AUTOSAR XML (schema 4-2-2)
package /AUTOSAR_Dem/SwComponentTypes
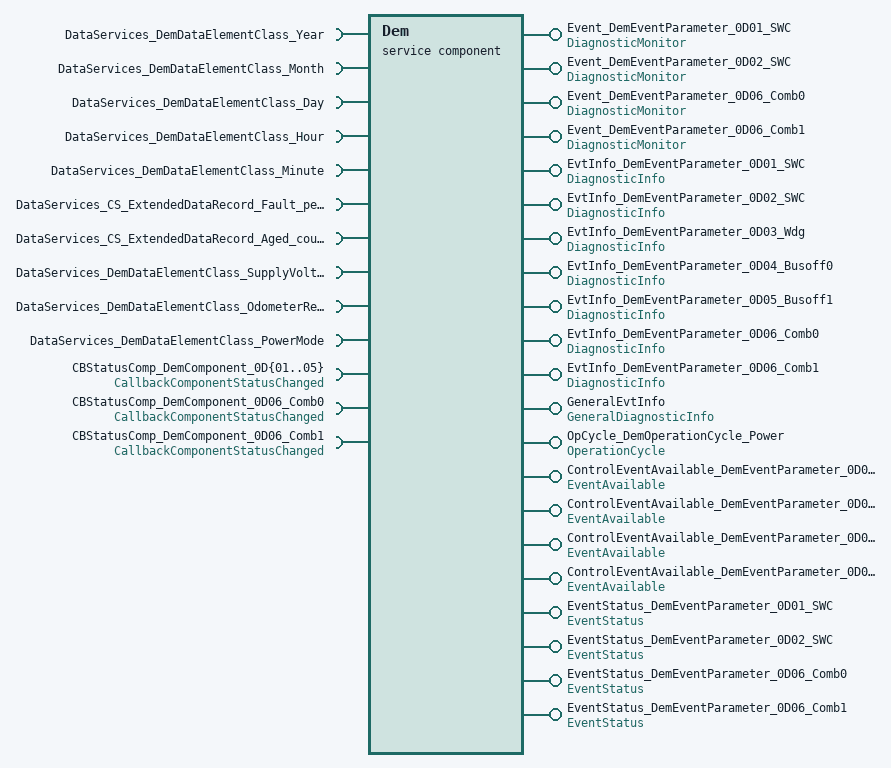
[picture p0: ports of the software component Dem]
  service sw component type Dem
    21 x provide port:
      Event_DemEventParameter_0D01_SWC: provided-interface=DiagnosticMonitor
        provided-com-specs:
          operation=SetEventStatus, queue-length=1
          operation=SetEventStatusWithEnvdata, queue-length=1
          operation=ResetEventStatus, queue-length=1
          operation=PrestoreFreezeFrame, queue-length=1
          operation=ClearPrestoredFreezeFrame, queue-length=1
          operation=ResetEventDebounceStatus, queue-length=1
      Event_DemEventParameter_0D02_SWC: provided-interface=DiagnosticMonitor
        provided-com-specs:
          operation=SetEventStatus, queue-length=1
          operation=SetEventStatusWithEnvdata, queue-length=1
          operation=ResetEventStatus, queue-length=1
          operation=PrestoreFreezeFrame, queue-length=1
          operation=ClearPrestoredFreezeFrame, queue-length=1
          operation=ResetEventDebounceStatus, queue-length=1
      Event_DemEventParameter_0D06_Comb0: provided-interface=DiagnosticMonitor
        provided-com-specs:
          operation=SetEventStatus, queue-length=1
          operation=SetEventStatusWithEnvdata, queue-length=1
          operation=ResetEventStatus, queue-length=1
          operation=PrestoreFreezeFrame, queue-length=1
          operation=ClearPrestoredFreezeFrame, queue-length=1
          operation=ResetEventDebounceStatus, queue-length=1
      Event_DemEventParameter_0D06_Comb1: provided-interface=DiagnosticMonitor
        provided-com-specs:
          operation=SetEventStatus, queue-length=1
          operation=SetEventStatusWithEnvdata, queue-length=1
          operation=ResetEventStatus, queue-length=1
          operation=PrestoreFreezeFrame, queue-length=1
          operation=ClearPrestoredFreezeFrame, queue-length=1
          operation=ResetEventDebounceStatus, queue-length=1
      EvtInfo_DemEventParameter_0D01_SWC: provided-interface=DiagnosticInfo
        provided-com-specs:
          operation=DiagnosticInfo/GetEventStatus, queue-length=1
          operation=DiagnosticInfo/GetEventFailed, queue-length=1
          operation=DiagnosticInfo/GetEventTested, queue-length=1
          operation=DiagnosticInfo/GetDTCOfEvent, queue-length=1
          operation=DiagnosticInfo/GetDebouncingOfEvent, queue-length=1
          operation=DiagnosticInfo/GetFaultDetectionCounter, queue-length=1
          operation=DiagnosticInfo/GetEventExtendedDataRecord, queue-length=1
          operation=DiagnosticInfo/GetEventExtendedDataRecordEx, queue-length=1
          operation=DiagnosticInfo/GetEventFreezeFrameData, queue-length=1
          operation=DiagnosticInfo/GetEventFreezeFrameDataEx, queue-length=1
      EvtInfo_DemEventParameter_0D02_SWC: provided-interface=DiagnosticInfo
        provided-com-specs:
          operation=DiagnosticInfo/GetEventStatus, queue-length=1
          operation=DiagnosticInfo/GetEventFailed, queue-length=1
          operation=DiagnosticInfo/GetEventTested, queue-length=1
          operation=DiagnosticInfo/GetDTCOfEvent, queue-length=1
          operation=DiagnosticInfo/GetDebouncingOfEvent, queue-length=1
          operation=DiagnosticInfo/GetFaultDetectionCounter, queue-length=1
          operation=DiagnosticInfo/GetEventExtendedDataRecord, queue-length=1
          operation=DiagnosticInfo/GetEventExtendedDataRecordEx, queue-length=1
          operation=DiagnosticInfo/GetEventFreezeFrameData, queue-length=1
          operation=DiagnosticInfo/GetEventFreezeFrameDataEx, queue-length=1
      EvtInfo_DemEventParameter_0D03_Wdg: provided-interface=DiagnosticInfo
        provided-com-specs:
          operation=DiagnosticInfo/GetEventStatus, queue-length=1
          operation=DiagnosticInfo/GetEventFailed, queue-length=1
          operation=DiagnosticInfo/GetEventTested, queue-length=1
          operation=DiagnosticInfo/GetDTCOfEvent, queue-length=1
          operation=DiagnosticInfo/GetDebouncingOfEvent, queue-length=1
          operation=DiagnosticInfo/GetFaultDetectionCounter, queue-length=1
          operation=DiagnosticInfo/GetEventExtendedDataRecord, queue-length=1
          operation=DiagnosticInfo/GetEventExtendedDataRecordEx, queue-length=1
          operation=DiagnosticInfo/GetEventFreezeFrameData, queue-length=1
          operation=DiagnosticInfo/GetEventFreezeFrameDataEx, queue-length=1
      EvtInfo_DemEventParameter_0D04_Busoff0: provided-interface=DiagnosticInfo
        provided-com-specs:
          operation=DiagnosticInfo/GetEventStatus, queue-length=1
          operation=DiagnosticInfo/GetEventFailed, queue-length=1
          operation=DiagnosticInfo/GetEventTested, queue-length=1
          operation=DiagnosticInfo/GetDTCOfEvent, queue-length=1
          operation=DiagnosticInfo/GetDebouncingOfEvent, queue-length=1
          operation=DiagnosticInfo/GetFaultDetectionCounter, queue-length=1
          operation=DiagnosticInfo/GetEventExtendedDataRecord, queue-length=1
          operation=DiagnosticInfo/GetEventExtendedDataRecordEx, queue-length=1
          operation=DiagnosticInfo/GetEventFreezeFrameData, queue-length=1
          operation=DiagnosticInfo/GetEventFreezeFrameDataEx, queue-length=1
      EvtInfo_DemEventParameter_0D05_Busoff1: provided-interface=DiagnosticInfo
        provided-com-specs:
          operation=DiagnosticInfo/GetEventStatus, queue-length=1
          operation=DiagnosticInfo/GetEventFailed, queue-length=1
          operation=DiagnosticInfo/GetEventTested, queue-length=1
          operation=DiagnosticInfo/GetDTCOfEvent, queue-length=1
          operation=DiagnosticInfo/GetDebouncingOfEvent, queue-length=1
          operation=DiagnosticInfo/GetFaultDetectionCounter, queue-length=1
          operation=DiagnosticInfo/GetEventExtendedDataRecord, queue-length=1
          operation=DiagnosticInfo/GetEventExtendedDataRecordEx, queue-length=1
          operation=DiagnosticInfo/GetEventFreezeFrameData, queue-length=1
          operation=DiagnosticInfo/GetEventFreezeFrameDataEx, queue-length=1
      EvtInfo_DemEventParameter_0D06_Comb0: provided-interface=DiagnosticInfo
        provided-com-specs:
          operation=DiagnosticInfo/GetEventStatus, queue-length=1
          operation=DiagnosticInfo/GetEventFailed, queue-length=1
          operation=DiagnosticInfo/GetEventTested, queue-length=1
          operation=DiagnosticInfo/GetDTCOfEvent, queue-length=1
          operation=DiagnosticInfo/GetDebouncingOfEvent, queue-length=1
          operation=DiagnosticInfo/GetFaultDetectionCounter, queue-length=1
          operation=DiagnosticInfo/GetEventExtendedDataRecord, queue-length=1
          operation=DiagnosticInfo/GetEventExtendedDataRecordEx, queue-length=1
          operation=DiagnosticInfo/GetEventFreezeFrameData, queue-length=1
          operation=DiagnosticInfo/GetEventFreezeFrameDataEx, queue-length=1
      EvtInfo_DemEventParameter_0D06_Comb1: provided-interface=DiagnosticInfo
        provided-com-specs:
          operation=DiagnosticInfo/GetEventStatus, queue-length=1
          operation=DiagnosticInfo/GetEventFailed, queue-length=1
          operation=DiagnosticInfo/GetEventTested, queue-length=1
          operation=DiagnosticInfo/GetDTCOfEvent, queue-length=1
          operation=DiagnosticInfo/GetDebouncingOfEvent, queue-length=1
          operation=DiagnosticInfo/GetFaultDetectionCounter, queue-length=1
          operation=DiagnosticInfo/GetEventExtendedDataRecord, queue-length=1
          operation=DiagnosticInfo/GetEventExtendedDataRecordEx, queue-length=1
          operation=DiagnosticInfo/GetEventFreezeFrameData, queue-length=1
          operation=DiagnosticInfo/GetEventFreezeFrameDataEx, queue-length=1
      GeneralEvtInfo: provided-interface=GeneralDiagnosticInfo
        provided-com-specs:
          operation=GeneralDiagnosticInfo/GetEventStatus, queue-length=1
          operation=GeneralDiagnosticInfo/GetEventFailed, queue-length=1
          operation=GeneralDiagnosticInfo/GetEventTested, queue-length=1
          operation=GeneralDiagnosticInfo/GetDTCOfEvent, queue-length=1
          operation=GeneralDiagnosticInfo/GetDebouncingOfEvent, queue-length=1
          operation=GeneralDiagnosticInfo/GetFaultDetectionCounter, queue-length=1
          operation=GeneralDiagnosticInfo/GetEventExtendedDataRecord, queue-length=1
          operation=GeneralDiagnosticInfo/GetEventFreezeFrameData, queue-length=1
          operation=GeneralDiagnosticInfo/GetEventExtendedDataRecordEx, queue-length=1
          operation=GeneralDiagnosticInfo/GetEventFreezeFrameDataEx, queue-length=1
          operation=GetEventIdCausingLastDetError, queue-length=1
      OpCycle_DemOperationCycle_Power: provided-interface=OperationCycle
        provided-com-specs:
          operation=SetOperationCycleState, queue-length=1
          operation=GetOperationCycleState, queue-length=1
          operation=GetCycleQualified, queue-length=1
          operation=SetCycleQualified, queue-length=1
      ControlEventAvailable_DemEventParameter_0D01_SWC: server-com-spec{operation=SetEventAvailable, queue-length=1}, provided-interface=EventAvailable
      ControlEventAvailable_DemEventParameter_0D02_SWC: server-com-spec{operation=SetEventAvailable, queue-length=1}, provided-interface=EventAvailable
      ControlEventAvailable_DemEventParameter_0D06_Comb0: server-com-spec{operation=SetEventAvailable, queue-length=1}, provided-interface=EventAvailable
      ControlEventAvailable_DemEventParameter_0D06_Comb1: server-com-spec{operation=SetEventAvailable, queue-length=1}, provided-interface=EventAvailable
      EventStatus_DemEventParameter_0D01_SWC: server-com-spec{operation=SetWIRStatus, queue-length=1}, provided-interface=EventStatus
      EventStatus_DemEventParameter_0D02_SWC: server-com-spec{operation=SetWIRStatus, queue-length=1}, provided-interface=EventStatus
      EventStatus_DemEventParameter_0D06_Comb0: server-com-spec{operation=SetWIRStatus, queue-length=1}, provided-interface=EventStatus
      EventStatus_DemEventParameter_0D06_Comb1: server-com-spec{operation=SetWIRStatus, queue-length=1}, provided-interface=EventStatus
    17 x require port:
      DataServices_DemDataElementClass_Year: required-interface=DataServices_DemDataElementClass_Year
      DataServices_DemDataElementClass_Month: required-interface=DataServices_DemDataElementClass_Month
      DataServices_DemDataElementClass_Day: required-interface=DataServices_DemDataElementClass_Day
      DataServices_DemDataElementClass_Hour: required-interface=DataServices_DemDataElementClass_Hour
      DataServices_DemDataElementClass_Minute: required-interface=DataServices_DemDataElementClass_Minute
      DataServices_CS_ExtendedDataRecord_Fault_pending_counter: required-interface=DataServices_CS_ExtendedDataRecord_Fault_pending_counter
      DataServices_CS_ExtendedDataRecord_Aged_counter: required-interface=DataServices_CS_ExtendedDataRecord_Aged_counter
      DataServices_DemDataElementClass_SupplyVoltage: required-interface=DataServices_DemDataElementClass_SupplyVoltage
      DataServices_DemDataElementClass_OdometerReading: required-interface=DataServices_DemDataElementClass_OdometerReading
      DataServices_DemDataElementClass_PowerMode: required-interface=DataServices_DemDataElementClass_PowerMode
      CBStatusComp_DemComponent_0D{01..05}: required-interface=CallbackComponentStatusChanged
      CBStatusComp_DemComponent_0D06_Comb0: required-interface=CallbackComponentStatusChanged
      CBStatusComp_DemComponent_0D06_Comb1: required-interface=CallbackComponentStatusChanged
    behavior IntBeh_Dem: handle-termination-and-restart=NO-SUPPORT, included-data-type-set=data-type=[Dem_DTCFormatType, Dem_DTCOriginType, Dem_EventIdType, Dem_UdsStatusByteType, Dem_EventStatusType, Dem_DebugDataType, Dem_IndicatorIdType, Dem_IndicatorStatusType, Dem_InitMonitorReasonType, Dem_MaxDataValueType, Dem_OperationCycleIdType, Dem_OperationCycleStateType, Dem_DebouncingStateType, Dem_DebounceResetStatusType]
      117 x operation invoked event:
        Ev_SES_DemEventParameter_0D01_SWC: start-on-event=SetEventStatus, operation=Event_DemEventParameter_0D01_SWC.SetEventStatus
        Ev_SESWE_DemEventParameter_0D01_SWC: start-on-event=SetEventStatusWithEnvdata, operation=Event_DemEventParameter_0D01_SWC.SetEventStatusWithEnvdata
        Ev_RES_DemEventParameter_0D01_SWC: start-on-event=ResetEventStatus, operation=Event_DemEventParameter_0D01_SWC.ResetEventStatus
        Ev_CPFF_DemEventParameter_0D01_SWC: start-on-event=ClearPrestoredFreezeFrame, operation=Event_DemEventParameter_0D01_SWC.ClearPrestoredFreezeFrame
        Ev_PFF_DemEventParameter_0D01_SWC: start-on-event=PrestoreFreezeFrame, operation=Event_DemEventParameter_0D01_SWC.PrestoreFreezeFrame
        Ev_RDS_DemEventParameter_0D01_SWC: start-on-event=ResetEventDebounceStatus, operation=Event_DemEventParameter_0D01_SWC.ResetEventDebounceStatus
        Ev_SES_DemEventParameter_0D02_SWC: start-on-event=SetEventStatus, operation=Event_DemEventParameter_0D02_SWC.SetEventStatus
        Ev_SESWE_DemEventParameter_0D02_SWC: start-on-event=SetEventStatusWithEnvdata, operation=Event_DemEventParameter_0D02_SWC.SetEventStatusWithEnvdata
        Ev_RES_DemEventParameter_0D02_SWC: start-on-event=ResetEventStatus, operation=Event_DemEventParameter_0D02_SWC.ResetEventStatus
        Ev_CPFF_DemEventParameter_0D02_SWC: start-on-event=ClearPrestoredFreezeFrame, operation=Event_DemEventParameter_0D02_SWC.ClearPrestoredFreezeFrame
        Ev_PFF_DemEventParameter_0D02_SWC: start-on-event=PrestoreFreezeFrame, operation=Event_DemEventParameter_0D02_SWC.PrestoreFreezeFrame
        Ev_RDS_DemEventParameter_0D02_SWC: start-on-event=ResetEventDebounceStatus, operation=Event_DemEventParameter_0D02_SWC.ResetEventDebounceStatus
        Ev_SES_DemEventParameter_0D06_Comb0: start-on-event=SetEventStatus, operation=Event_DemEventParameter_0D06_Comb0.SetEventStatus
        Ev_SESWE_DemEventParameter_0D06_Comb0: start-on-event=SetEventStatusWithEnvdata, operation=Event_DemEventParameter_0D06_Comb0.SetEventStatusWithEnvdata
        Ev_RES_DemEventParameter_0D06_Comb0: start-on-event=ResetEventStatus, operation=Event_DemEventParameter_0D06_Comb0.ResetEventStatus
        Ev_CPFF_DemEventParameter_0D06_Comb0: start-on-event=ClearPrestoredFreezeFrame, operation=Event_DemEventParameter_0D06_Comb0.ClearPrestoredFreezeFrame
        Ev_PFF_DemEventParameter_0D06_Comb0: start-on-event=PrestoreFreezeFrame, operation=Event_DemEventParameter_0D06_Comb0.PrestoreFreezeFrame
        Ev_RDS_DemEventParameter_0D06_Comb0: start-on-event=ResetEventDebounceStatus, operation=Event_DemEventParameter_0D06_Comb0.ResetEventDebounceStatus
        Ev_SES_DemEventParameter_0D06_Comb1: start-on-event=SetEventStatus, operation=Event_DemEventParameter_0D06_Comb1.SetEventStatus
        Ev_SESWE_DemEventParameter_0D06_Comb1: start-on-event=SetEventStatusWithEnvdata, operation=Event_DemEventParameter_0D06_Comb1.SetEventStatusWithEnvdata
        Ev_RES_DemEventParameter_0D06_Comb1: start-on-event=ResetEventStatus, operation=Event_DemEventParameter_0D06_Comb1.ResetEventStatus
        Ev_CPFF_DemEventParameter_0D06_Comb1: start-on-event=ClearPrestoredFreezeFrame, operation=Event_DemEventParameter_0D06_Comb1.ClearPrestoredFreezeFrame
        Ev_PFF_DemEventParameter_0D06_Comb1: start-on-event=PrestoreFreezeFrame, operation=Event_DemEventParameter_0D06_Comb1.PrestoreFreezeFrame
        Ev_RDS_DemEventParameter_0D06_Comb1: start-on-event=ResetEventDebounceStatus, operation=Event_DemEventParameter_0D06_Comb1.ResetEventDebounceStatus
        Ev_GES_DemEventParameter_0D01_SWC: start-on-event=GetEventStatus, operation=EvtInfo_DemEventParameter_0D01_SWC.GetEventStatus
        Ev_GEF_DemEventParameter_0D01_SWC: start-on-event=GetEventFailed, operation=EvtInfo_DemEventParameter_0D01_SWC.GetEventFailed
        Ev_GET_DemEventParameter_0D01_SWC: start-on-event=GetEventTested, operation=EvtInfo_DemEventParameter_0D01_SWC.GetEventTested
        Ev_GDOE_DemEventParameter_0D01_SWC: start-on-event=GetDTCOfEvent, operation=EvtInfo_DemEventParameter_0D01_SWC.GetDTCOfEvent
        Ev_GETDOE_DemEventParameter_0D01_SWC: start-on-event=GetDebouncingOfEvent, operation=EvtInfo_DemEventParameter_0D01_SWC.GetDebouncingOfEvent
        Ev_GFDC_DemEventParameter_0D01_SWC: start-on-event=GetFaultDetectionCounter, operation=EvtInfo_DemEventParameter_0D01_SWC.GetFaultDetectionCounter
        Ev_GEED_DemEventParameter_0D01_SWC: start-on-event=GetEventExtendedDataRecord, operation=EvtInfo_DemEventParameter_0D01_SWC.GetEventExtendedDataRecord
        Ev_GEEDR_DemEventParameter_0D01_SWC: start-on-event=GetEventExtendedDataRecordEx, operation=EvtInfo_DemEventParameter_0D01_SWC.GetEventExtendedDataRecordEx
        Ev_GEFFD_DemEventParameter_0D01_SWC: start-on-event=GetEventFreezeFrameData, operation=EvtInfo_DemEventParameter_0D01_SWC.GetEventFreezeFrameData
        Ev_GEFFDE_DemEventParameter_0D01_SWC: start-on-event=GetEventFreezeFrameDataEx, operation=EvtInfo_DemEventParameter_0D01_SWC.GetEventFreezeFrameDataEx
        Ev_GES_DemEventParameter_0D02_SWC: start-on-event=GetEventStatus, operation=EvtInfo_DemEventParameter_0D02_SWC.GetEventStatus
        Ev_GEF_DemEventParameter_0D02_SWC: start-on-event=GetEventFailed, operation=EvtInfo_DemEventParameter_0D02_SWC.GetEventFailed
        Ev_GET_DemEventParameter_0D02_SWC: start-on-event=GetEventTested, operation=EvtInfo_DemEventParameter_0D02_SWC.GetEventTested
        Ev_GDOE_DemEventParameter_0D02_SWC: start-on-event=GetDTCOfEvent, operation=EvtInfo_DemEventParameter_0D02_SWC.GetDTCOfEvent
        Ev_GETDOE_DemEventParameter_0D02_SWC: start-on-event=GetDebouncingOfEvent, operation=EvtInfo_DemEventParameter_0D02_SWC.GetDebouncingOfEvent
        Ev_GFDC_DemEventParameter_0D02_SWC: start-on-event=GetFaultDetectionCounter, operation=EvtInfo_DemEventParameter_0D02_SWC.GetFaultDetectionCounter
        Ev_GEED_DemEventParameter_0D02_SWC: start-on-event=GetEventExtendedDataRecord, operation=EvtInfo_DemEventParameter_0D02_SWC.GetEventExtendedDataRecord
        Ev_GEEDR_DemEventParameter_0D02_SWC: start-on-event=GetEventExtendedDataRecordEx, operation=EvtInfo_DemEventParameter_0D02_SWC.GetEventExtendedDataRecordEx
        Ev_GEFFD_DemEventParameter_0D02_SWC: start-on-event=GetEventFreezeFrameData, operation=EvtInfo_DemEventParameter_0D02_SWC.GetEventFreezeFrameData
        Ev_GEFFDE_DemEventParameter_0D02_SWC: start-on-event=GetEventFreezeFrameDataEx, operation=EvtInfo_DemEventParameter_0D02_SWC.GetEventFreezeFrameDataEx
        Ev_GES_DemEventParameter_0D03_Wdg: start-on-event=GetEventStatus, operation=EvtInfo_DemEventParameter_0D03_Wdg.GetEventStatus
        Ev_GEF_DemEventParameter_0D03_Wdg: start-on-event=GetEventFailed, operation=EvtInfo_DemEventParameter_0D03_Wdg.GetEventFailed
        Ev_GET_DemEventParameter_0D03_Wdg: start-on-event=GetEventTested, operation=EvtInfo_DemEventParameter_0D03_Wdg.GetEventTested
        Ev_GDOE_DemEventParameter_0D03_Wdg: start-on-event=GetDTCOfEvent, operation=EvtInfo_DemEventParameter_0D03_Wdg.GetDTCOfEvent
        Ev_GETDOE_DemEventParameter_0D03_Wdg: start-on-event=GetDebouncingOfEvent, operation=EvtInfo_DemEventParameter_0D03_Wdg.GetDebouncingOfEvent
        Ev_GFDC_DemEventParameter_0D03_Wdg: start-on-event=GetFaultDetectionCounter, operation=EvtInfo_DemEventParameter_0D03_Wdg.GetFaultDetectionCounter
        Ev_GEED_DemEventParameter_0D03_Wdg: start-on-event=GetEventExtendedDataRecord, operation=EvtInfo_DemEventParameter_0D03_Wdg.GetEventExtendedDataRecord
        Ev_GEEDR_DemEventParameter_0D03_Wdg: start-on-event=GetEventExtendedDataRecordEx, operation=EvtInfo_DemEventParameter_0D03_Wdg.GetEventExtendedDataRecordEx
        Ev_GEFFD_DemEventParameter_0D03_Wdg: start-on-event=GetEventFreezeFrameData, operation=EvtInfo_DemEventParameter_0D03_Wdg.GetEventFreezeFrameData
        Ev_GEFFDE_DemEventParameter_0D03_Wdg: start-on-event=GetEventFreezeFrameDataEx, operation=EvtInfo_DemEventParameter_0D03_Wdg.GetEventFreezeFrameDataEx
        Ev_GES_DemEventParameter_0D04_Busoff0: start-on-event=GetEventStatus, operation=EvtInfo_DemEventParameter_0D04_Busoff0.GetEventStatus
        Ev_GEF_DemEventParameter_0D04_Busoff0: start-on-event=GetEventFailed, operation=EvtInfo_DemEventParameter_0D04_Busoff0.GetEventFailed
        Ev_GET_DemEventParameter_0D04_Busoff0: start-on-event=GetEventTested, operation=EvtInfo_DemEventParameter_0D04_Busoff0.GetEventTested
        Ev_GDOE_DemEventParameter_0D04_Busoff0: start-on-event=GetDTCOfEvent, operation=EvtInfo_DemEventParameter_0D04_Busoff0.GetDTCOfEvent
        Ev_GETDOE_DemEventParameter_0D04_Busoff0: start-on-event=GetDebouncingOfEvent, operation=EvtInfo_DemEventParameter_0D04_Busoff0.GetDebouncingOfEvent
        Ev_GFDC_DemEventParameter_0D04_Busoff0: start-on-event=GetFaultDetectionCounter, operation=EvtInfo_DemEventParameter_0D04_Busoff0.GetFaultDetectionCounter
        Ev_GEED_DemEventParameter_0D04_Busoff0: start-on-event=GetEventExtendedDataRecord, operation=EvtInfo_DemEventParameter_0D04_Busoff0.GetEventExtendedDataRecord
        Ev_GEEDR_DemEventParameter_0D04_Busoff0: start-on-event=GetEventExtendedDataRecordEx, operation=EvtInfo_DemEventParameter_0D04_Busoff0.GetEventExtendedDataRecordEx
        Ev_GEFFD_DemEventParameter_0D04_Busoff0: start-on-event=GetEventFreezeFrameData, operation=EvtInfo_DemEventParameter_0D04_Busoff0.GetEventFreezeFrameData
        Ev_GEFFDE_DemEventParameter_0D04_Busoff0: start-on-event=GetEventFreezeFrameDataEx, operation=EvtInfo_DemEventParameter_0D04_Busoff0.GetEventFreezeFrameDataEx
        Ev_GES_DemEventParameter_0D05_Busoff1: start-on-event=GetEventStatus, operation=EvtInfo_DemEventParameter_0D05_Busoff1.GetEventStatus
        Ev_GEF_DemEventParameter_0D05_Busoff1: start-on-event=GetEventFailed, operation=EvtInfo_DemEventParameter_0D05_Busoff1.GetEventFailed
        Ev_GET_DemEventParameter_0D05_Busoff1: start-on-event=GetEventTested, operation=EvtInfo_DemEventParameter_0D05_Busoff1.GetEventTested
        Ev_GDOE_DemEventParameter_0D05_Busoff1: start-on-event=GetDTCOfEvent, operation=EvtInfo_DemEventParameter_0D05_Busoff1.GetDTCOfEvent
        Ev_GETDOE_DemEventParameter_0D05_Busoff1: start-on-event=GetDebouncingOfEvent, operation=EvtInfo_DemEventParameter_0D05_Busoff1.GetDebouncingOfEvent
        Ev_GFDC_DemEventParameter_0D05_Busoff1: start-on-event=GetFaultDetectionCounter, operation=EvtInfo_DemEventParameter_0D05_Busoff1.GetFaultDetectionCounter
        Ev_GEED_DemEventParameter_0D05_Busoff1: start-on-event=GetEventExtendedDataRecord, operation=EvtInfo_DemEventParameter_0D05_Busoff1.GetEventExtendedDataRecord
        Ev_GEEDR_DemEventParameter_0D05_Busoff1: start-on-event=GetEventExtendedDataRecordEx, operation=EvtInfo_DemEventParameter_0D05_Busoff1.GetEventExtendedDataRecordEx
        Ev_GEFFD_DemEventParameter_0D05_Busoff1: start-on-event=GetEventFreezeFrameData, operation=EvtInfo_DemEventParameter_0D05_Busoff1.GetEventFreezeFrameData
        Ev_GEFFDE_DemEventParameter_0D05_Busoff1: start-on-event=GetEventFreezeFrameDataEx, operation=EvtInfo_DemEventParameter_0D05_Busoff1.GetEventFreezeFrameDataEx
        Ev_GES_DemEventParameter_0D06_Comb0: start-on-event=GetEventStatus, operation=EvtInfo_DemEventParameter_0D06_Comb0.GetEventStatus
        Ev_GEF_DemEventParameter_0D06_Comb0: start-on-event=GetEventFailed, operation=EvtInfo_DemEventParameter_0D06_Comb0.GetEventFailed
        Ev_GET_DemEventParameter_0D06_Comb0: start-on-event=GetEventTested, operation=EvtInfo_DemEventParameter_0D06_Comb0.GetEventTested
        Ev_GDOE_DemEventParameter_0D06_Comb0: start-on-event=GetDTCOfEvent, operation=EvtInfo_DemEventParameter_0D06_Comb0.GetDTCOfEvent
        Ev_GETDOE_DemEventParameter_0D06_Comb0: start-on-event=GetDebouncingOfEvent, operation=EvtInfo_DemEventParameter_0D06_Comb0.GetDebouncingOfEvent
        Ev_GFDC_DemEventParameter_0D06_Comb0: start-on-event=GetFaultDetectionCounter, operation=EvtInfo_DemEventParameter_0D06_Comb0.GetFaultDetectionCounter
        Ev_GEED_DemEventParameter_0D06_Comb0: start-on-event=GetEventExtendedDataRecord, operation=EvtInfo_DemEventParameter_0D06_Comb0.GetEventExtendedDataRecord
        Ev_GEEDR_DemEventParameter_0D06_Comb0: start-on-event=GetEventExtendedDataRecordEx, operation=EvtInfo_DemEventParameter_0D06_Comb0.GetEventExtendedDataRecordEx
        Ev_GEFFD_DemEventParameter_0D06_Comb0: start-on-event=GetEventFreezeFrameData, operation=EvtInfo_DemEventParameter_0D06_Comb0.GetEventFreezeFrameData
        Ev_GEFFDE_DemEventParameter_0D06_Comb0: start-on-event=GetEventFreezeFrameDataEx, operation=EvtInfo_DemEventParameter_0D06_Comb0.GetEventFreezeFrameDataEx
        Ev_GES_DemEventParameter_0D06_Comb1: start-on-event=GetEventStatus, operation=EvtInfo_DemEventParameter_0D06_Comb1.GetEventStatus
        Ev_GEF_DemEventParameter_0D06_Comb1: start-on-event=GetEventFailed, operation=EvtInfo_DemEventParameter_0D06_Comb1.GetEventFailed
        Ev_GET_DemEventParameter_0D06_Comb1: start-on-event=GetEventTested, operation=EvtInfo_DemEventParameter_0D06_Comb1.GetEventTested
        Ev_GDOE_DemEventParameter_0D06_Comb1: start-on-event=GetDTCOfEvent, operation=EvtInfo_DemEventParameter_0D06_Comb1.GetDTCOfEvent
        Ev_GETDOE_DemEventParameter_0D06_Comb1: start-on-event=GetDebouncingOfEvent, operation=EvtInfo_DemEventParameter_0D06_Comb1.GetDebouncingOfEvent
        Ev_GFDC_DemEventParameter_0D06_Comb1: start-on-event=GetFaultDetectionCounter, operation=EvtInfo_DemEventParameter_0D06_Comb1.GetFaultDetectionCounter
        Ev_GEED_DemEventParameter_0D06_Comb1: start-on-event=GetEventExtendedDataRecord, operation=EvtInfo_DemEventParameter_0D06_Comb1.GetEventExtendedDataRecord
        Ev_GEEDR_DemEventParameter_0D06_Comb1: start-on-event=GetEventExtendedDataRecordEx, operation=EvtInfo_DemEventParameter_0D06_Comb1.GetEventExtendedDataRecordEx
        Ev_GEFFD_DemEventParameter_0D06_Comb1: start-on-event=GetEventFreezeFrameData, operation=EvtInfo_DemEventParameter_0D06_Comb1.GetEventFreezeFrameData
        Ev_GEFFDE_DemEventParameter_0D06_Comb1: start-on-event=GetEventFreezeFrameDataEx, operation=EvtInfo_DemEventParameter_0D06_Comb1.GetEventFreezeFrameDataEx
        GDI_GDOE_GetDebouncingOfEvent: start-on-event=GetDebouncingOfEvent_GeneralEvtInfo, operation=GeneralEvtInfo.GetDebouncingOfEvent
        GDI_GES_GetEventStatus: start-on-event=Dem_GetEventStatus_GeneralEvtInfo, operation=GeneralEvtInfo.GetEventStatus
        GDI_GEF_GetEventFailed: start-on-event=Dem_GetEventFailed_GeneralEvtInfo, operation=GeneralEvtInfo.GetEventFailed
        GDI_GET_GetEventTested: start-on-event=Dem_GetEventTested_GeneralEvtInfo, operation=GeneralEvtInfo.GetEventTested
        GDI_GDE_GetDTCOfEvent: start-on-event=Dem_GetDTCOfEvent_GeneralEvtInfo, operation=GeneralEvtInfo.GetDTCOfEvent
        GDI_GFDC_GetFaultDetectionCounter: start-on-event=Dem_GetFaultDetectionCounter_GeneralEvtInfo, operation=GeneralEvtInfo.GetFaultDetectionCounter
        GDI_GEED_GetEventExtendedDataRecord: start-on-event=Dem_GetEventExtendedDataRecord_GeneralEvtInfo, operation=GeneralEvtInfo.GetEventExtendedDataRecord
        GDI_GEFFD_GetEventFreezeFrameData: start-on-event=Dem_GetEventFreezeFrameData_GeneralEvtInfo, operation=GeneralEvtInfo.GetEventFreezeFrameData
        GDI_GEED_GetEventExtendedDataRecordEx: start-on-event=Dem_GetEventExtendedDataRecordEx_GeneralEvtInfo, operation=GeneralEvtInfo.GetEventExtendedDataRecordEx
        GDI_GEFFD_GetEventFreezeFrameDataEx: start-on-event=Dem_GetEventFreezeFrameDataEx_GeneralEvtInfo, operation=GeneralEvtInfo.GetEventFreezeFrameDataEx
        Ev_GEICLDE_GetEventIdCausingLastDetError: start-on-event=Dem_GetEventIdCausingLastDetError, operation=GeneralEvtInfo.GetEventIdCausingLastDetError
        OpCycle_OCS_DemOperationCycle_Power: start-on-event=SetOperationCycleState, operation=OpCycle_DemOperationCycle_Power.SetOperationCycleState
        OpCycle_GOCS_DemOperationCycle_Power: start-on-event=GetOperationCycleState, operation=OpCycle_DemOperationCycle_Power.GetOperationCycleState
        OpCycle_GCQ_DemOperationCycle_Power: start-on-event=GetCycleQualified, operation=OpCycle_DemOperationCycle_Power.GetCycleQualified
        OpCycle_SCQ_DemOperationCycle_Power: start-on-event=SetCycleQualified, operation=OpCycle_DemOperationCycle_Power.SetCycleQualified
        Ev_SetWIRStatus_DemEventParameter_0D01_SWC: start-on-event=SetWIRStatus, operation=EventStatus_DemEventParameter_0D01_SWC.SetWIRStatus
        Ev_SetWIRStatus_DemEventParameter_0D02_SWC: start-on-event=SetWIRStatus, operation=EventStatus_DemEventParameter_0D02_SWC.SetWIRStatus
        Ev_SetWIRStatus_DemEventParameter_0D06_Comb0: start-on-event=SetWIRStatus, operation=EventStatus_DemEventParameter_0D06_Comb0.SetWIRStatus
        Ev_SetWIRStatus_DemEventParameter_0D06_Comb1: start-on-event=SetWIRStatus, operation=EventStatus_DemEventParameter_0D06_Comb1.SetWIRStatus
        EventAvailable_SetEventAvailable_DemEventParameter_0D01_SWC: start-on-event=SetEventAvailable, operation=ControlEventAvailable_DemEventParameter_0D01_SWC.SetEventAvailable
        EventAvailable_SetEventAvailable_DemEventParameter_0D02_SWC: start-on-event=SetEventAvailable, operation=ControlEventAvailable_DemEventParameter_0D02_SWC.SetEventAvailable
        EventAvailable_SetEventAvailable_DemEventParameter_0D06_Comb0: start-on-event=SetEventAvailable, operation=ControlEventAvailable_DemEventParameter_0D06_Comb0.SetEventAvailable
        EventAvailable_SetEventAvailable_DemEventParameter_0D06_Comb1: start-on-event=SetEventAvailable, operation=ControlEventAvailable_DemEventParameter_0D06_Comb1.SetEventAvailable
      port-api-options:
        {enable-take-address=true, indirect-api=false, port-defined-argument-value{value=EvtInfo_DemEventParameter_0D01_SWC:1, value-type=Dem_EventIdType}, port=EvtInfo_DemEventParameter_0D01_SWC}
        {enable-take-address=true, indirect-api=false, port-defined-argument-value{value=EvtInfo_DemEventParameter_0D02_SWC:2, value-type=Dem_EventIdType}, port=EvtInfo_DemEventParameter_0D02_SWC}
        {enable-take-address=true, indirect-api=false, port-defined-argument-value{value=EvtInfo_DemEventParameter_0D03_Wdg:3, value-type=Dem_EventIdType}, port=EvtInfo_DemEventParameter_0D03_Wdg}
        {enable-take-address=true, indirect-api=false, port-defined-argument-value{value=EvtInfo_DemEventParameter_0D04_Busoff0:4, value-type=Dem_EventIdType}, port=EvtInfo_DemEventParameter_0D04_Busoff0}
        {enable-take-address=true, indirect-api=false, port-defined-argument-value{value=EvtInfo_DemEventParameter_0D05_Busoff1:5, value-type=Dem_EventIdType}, port=EvtInfo_DemEventParameter_0D05_Busoff1}
        {enable-take-address=true, indirect-api=false, port-defined-argument-value{value=EvtInfo_DemEventParameter_0D06_Comb0:6, value-type=Dem_EventIdType}, port=EvtInfo_DemEventParameter_0D06_Comb0}
        {enable-take-address=true, indirect-api=false, port-defined-argument-value{value=EvtInfo_DemEventParameter_0D06_Comb1:7, value-type=Dem_EventIdType}, port=EvtInfo_DemEventParameter_0D06_Comb1}
        {enable-take-address=true, indirect-api=false, port-defined-argument-value{value=Event_DemEventParameter_0D01_SWC:1, value-type=Dem_EventIdType}, port=Event_DemEventParameter_0D01_SWC}
        {enable-take-address=true, indirect-api=false, port-defined-argument-value{value=EventStatus_DemEventParameter_0D01_SWC:1, value-type=Dem_EventIdType}, port=EventStatus_DemEventParameter_0D01_SWC}
        {enable-take-address=true, indirect-api=false, port-defined-argument-value{value=Event_DemEventParameter_0D02_SWC:2, value-type=Dem_EventIdType}, port=Event_DemEventParameter_0D02_SWC}
        {enable-take-address=true, indirect-api=false, port-defined-argument-value{value=EventStatus_DemEventParameter_0D02_SWC:2, value-type=Dem_EventIdType}, port=EventStatus_DemEventParameter_0D02_SWC}
        {enable-take-address=true, indirect-api=false, port-defined-argument-value{value=Event_DemEventParameter_0D06_Comb0:6, value-type=Dem_EventIdType}, port=Event_DemEventParameter_0D06_Comb0}
        {enable-take-address=true, indirect-api=false, port-defined-argument-value{value=EventStatus_DemEventParameter_0D06_Comb0:6, value-type=Dem_EventIdType}, port=EventStatus_DemEventParameter_0D06_Comb0}
        {enable-take-address=true, indirect-api=false, port-defined-argument-value{value=Event_DemEventParameter_0D06_Comb1:7, value-type=Dem_EventIdType}, port=Event_DemEventParameter_0D06_Comb1}
        {enable-take-address=true, indirect-api=false, port-defined-argument-value{value=EventStatus_DemEventParameter_0D06_Comb1:7, value-type=Dem_EventIdType}, port=EventStatus_DemEventParameter_0D06_Comb1}
        {enable-take-address=true, indirect-api=false, port-defined-argument-value{value=OpCycle_DemOperationCycle_Power:0, value-type=Dem_OperationCycleIdType}, port=OpCycle_DemOperationCycle_Power}
        enable-take-address=true, indirect-api=false, port=GeneralEvtInfo
        {enable-take-address=true, indirect-api=false, port-defined-argument-value{value=ControlEventAvailable_DemEventParameter_0D01_SWC:1, value-type=Dem_EventIdType}, port=ControlEventAvailable_DemEventParameter_0D01_SWC}
        {enable-take-address=true, indirect-api=false, port-defined-argument-value{value=ControlEventAvailable_DemEventParameter_0D02_SWC:2, value-type=Dem_EventIdType}, port=ControlEventAvailable_DemEventParameter_0D02_SWC}
        {enable-take-address=true, indirect-api=false, port-defined-argument-value{value=ControlEventAvailable_DemEventParameter_0D06_Comb0:6, value-type=Dem_EventIdType}, port=ControlEventAvailable_DemEventParameter_0D06_Comb0}
        {enable-take-address=true, indirect-api=false, port-defined-argument-value{value=ControlEventAvailable_DemEventParameter_0D06_Comb1:7, value-type=Dem_EventIdType}, port=ControlEventAvailable_DemEventParameter_0D06_Comb1}
        enable-take-address=true, indirect-api=false, port=DataServices_DemDataElementClass_Year
        enable-take-address=true, indirect-api=false, port=DataServices_DemDataElementClass_Month
        enable-take-address=true, indirect-api=false, port=DataServices_DemDataElementClass_Day
        enable-take-address=true, indirect-api=false, port=DataServices_DemDataElementClass_Hour
        enable-take-address=true, indirect-api=false, port=DataServices_DemDataElementClass_Minute
        enable-take-address=true, indirect-api=false, port=DataServices_CS_ExtendedDataRecord_Fault_pending_counter
        enable-take-address=true, indirect-api=false, port=DataServices_CS_ExtendedDataRecord_Aged_counter
        enable-take-address=true, indirect-api=false, port=DataServices_DemDataElementClass_SupplyVoltage
        enable-take-address=true, indirect-api=false, port=DataServices_DemDataElementClass_OdometerReading
        enable-take-address=true, indirect-api=false, port=DataServices_DemDataElementClass_PowerMode
      45 x runnable:
        Dem_MainFunction
          17 x sync call, all with timeout=0.0:
            SSC_DataServices_DemDataElementClass_Year_ReadData: operation=DataServices_DemDataElementClass_Year.ReadData
            SSC_DataServices_DemDataElementClass_Month_ReadData: operation=DataServices_DemDataElementClass_Month.ReadData
            SSC_DataServices_DemDataElementClass_Day_ReadData: operation=DataServices_DemDataElementClass_Day.ReadData
            SSC_DataServices_DemDataElementClass_Hour_ReadData: operation=DataServices_DemDataElementClass_Hour.ReadData
            SSC_DataServices_DemDataElementClass_Minute_ReadData: operation=DataServices_DemDataElementClass_Minute.ReadData
            SSC_DataServices_CS_ExtendedDataRecord_Fault_pending_counter_ReadData: operation=DataServices_CS_ExtendedDataRecord_Fault_pending_counter.ReadData
            SSC_DataServices_CS_ExtendedDataRecord_Aged_counter_ReadData: operation=DataServices_CS_ExtendedDataRecord_Aged_counter.ReadData
            SSC_DataServices_DemDataElementClass_SupplyVoltage_ReadData: operation=DataServices_DemDataElementClass_SupplyVoltage.ReadData
            SSC_DataServices_DemDataElementClass_OdometerReading_ReadData: operation=DataServices_DemDataElementClass_OdometerReading.ReadData
            SSC_DataServices_DemDataElementClass_PowerMode_ReadData: operation=DataServices_DemDataElementClass_PowerMode.ReadData
            SSC_CBStatusComp_DemComponent_0D{01..05}: operation=CBStatusComp_DemComponent_0D{01..05}.ComponentStatusChanged
            SSC_CBStatusComp_DemComponent_0D06_Comb0: operation=CBStatusComp_DemComponent_0D06_Comb0.ComponentStatusChanged
            SSC_CBStatusComp_DemComponent_0D06_Comb1: operation=CBStatusComp_DemComponent_0D06_Comb1.ComponentStatusChanged
        SetEventStatus: arguments=[symbol=EventId, symbol=EventStatus], can-be-invoked-concurrently=true, symbol=Dem_SetEventStatus
        SetEventStatusWithEnvdata: arguments=[symbol=EventId, symbol=EventStatus, symbol=debug0, symbol=debug1], can-be-invoked-concurrently=true, symbol=Dem_SetEventStatusWithEnvData
        ResetEventStatus: runnable-entity-argument=symbol=EventId, can-be-invoked-concurrently=true, symbol=Dem_ResetEventStatus
        PrestoreFreezeFrame: runnable-entity-argument=symbol=EventId, can-be-invoked-concurrently=true, symbol=Dem_PrestoreFreezeFrame
        ClearPrestoredFreezeFrame: runnable-entity-argument=symbol=EventId, can-be-invoked-concurrently=true, symbol=Dem_ClearPrestoredFreezeFrame
        ResetEventDebounceStatus: arguments=[symbol=EventId, symbol=DebounceResetStatus], can-be-invoked-concurrently=true, symbol=Dem_ResetEventDebounceStatus
        GetEventStatus: arguments=[symbol=EventId, symbol=EventStatusExtended], can-be-invoked-concurrently=true, symbol=Dem_GetEventStatus
        GetEventFailed: arguments=[symbol=EventId, symbol=EventFailed], can-be-invoked-concurrently=true, symbol=Dem_GetEventFailed
        GetEventTested: arguments=[symbol=EventId, symbol=EventTested], can-be-invoked-concurrently=true, symbol=Dem_GetEventTested
        GetDTCOfEvent: arguments=[symbol=EventId, symbol=DTCFormat, symbol=DTCOfEvent], can-be-invoked-concurrently=true, symbol=Dem_GetDTCOfEvent
        GetDebouncingOfEvent: arguments=[symbol=EventId, symbol=DebouncingState], can-be-invoked-concurrently=true, symbol=Dem_GetDebouncingOfEvent
        GetFaultDetectionCounter: arguments=[symbol=EventId, symbol=FaultDetectionCounter], can-be-invoked-concurrently=true, symbol=Dem_GetFaultDetectionCounter
        SetWIRStatus: arguments=[symbol=EventId, symbol=WIRStatus], can-be-invoked-concurrently=true, symbol=Dem_SetWIRStatus
        GetEventExtendedDataRecord: arguments=[symbol=EventId, symbol=RecordNumber, symbol=DestBuffer], can-be-invoked-concurrently=true, symbol=Dem_GetEventExtendedDataRecordForRTE
        GetEventExtendedDataRecordEx: arguments=[symbol=EventId, symbol=RecordNumber, symbol=DestBuffer, symbol=BufSize], can-be-invoked-concurrently=true, symbol=Dem_GetEventExtendedDataRecordEx
        GetEventFreezeFrameData: arguments=[symbol=EventId, symbol=RecordNumber, symbol=ReportTotalRecord, symbol=DataId, symbol=DestBuffer], can-be-invoked-concurrently=true, symbol=Dem_GetEventFreezeFrameDataForRTE
        GetEventFreezeFrameDataEx: arguments=[symbol=EventId, symbol=RecordNumber, symbol=DataId, symbol=DestBuffer, symbol=BufSize], can-be-invoked-concurrently=true, symbol=Dem_GetEventFreezeFrameDataEx
        SetOperationCycleState: arguments=[symbol=OperationCycleId, symbol=CycleState], can-be-invoked-concurrently=true, symbol=Dem_SetOperationCycleState
        GetOperationCycleState: arguments=[symbol=OperationCycleId, symbol=CycleState], can-be-invoked-concurrently=true, symbol=Dem_GetOperationCycleState
        GetCycleQualified: arguments=[symbol=OperationCycleId, symbol=isQualified], can-be-invoked-concurrently=true, symbol=Dem_GetCycleQualified
        SetCycleQualified: runnable-entity-argument=symbol=OperationCycleId, can-be-invoked-concurrently=true, symbol=Dem_SetCycleQualified
        SetEnableCondition: arguments=[symbol=EnableConditionID, symbol=ConditionFulfilled], can-be-invoked-concurrently=true, symbol=Dem_SetEnableCondition
        GetEnableCondition: arguments=[symbol=EnableConditionID, symbol=ConditionFulfilled], can-be-invoked-concurrently=true, symbol=Dem_GetEnableCondition
        SetStorageCondition: arguments=[symbol=StorageConditionID, symbol=ConditionFulfilled], can-be-invoked-concurrently=true, symbol=Dem_SetStorageCondition
        GetStorageCondition: arguments=[symbol=StorageConditionID, symbol=ConditionFulfilled], can-be-invoked-concurrently=true, symbol=Dem_GetStorageCondition
        GetIndicatorStatus: arguments=[symbol=IndicatorId, symbol=IndicatorStatus], can-be-invoked-concurrently=true, symbol=Dem_GetIndicatorStatus
        SetDTCSuppression: arguments=[symbol=ClientId, symbol=SuppressionStatus], symbol=Dem_SetDTCSuppression
        GetDTCSuppression: arguments=[symbol=ClientId, symbol=SuppressionStatus], symbol=Dem_GetDTCSuppression
        GetEventMemoryOverflow: arguments=[symbol=ClientId, symbol=DTCOrigin, symbol=OverflowIndication], can-be-invoked-concurrently=true, symbol=Dem_GetEventMemoryOverflow
        GetNumberOfEventMemoryEntries: arguments=[symbol=ClientId, symbol=DTCOrigin, symbol=NumberOfEventMemoryEntries], can-be-invoked-concurrently=true, symbol=Dem_GetNumberOfEventMemoryEntries
        ClearDTC: runnable-entity-argument=symbol=ClientId, symbol=Dem_ClearDTC
        SelectDTC: arguments=[symbol=ClientId, symbol=DTC, symbol=DTCFormat, symbol=DTCOrigin], symbol=Dem_SelectDTC
        Dem_GetEventStatus_GeneralEvtInfo: arguments=[symbol=EventId, symbol=EventStatusExtended], can-be-invoked-concurrently=true
        Dem_GetEventFailed_GeneralEvtInfo: can-be-invoked-concurrently=true
        Dem_GetEventTested_GeneralEvtInfo: arguments=[symbol=EventId, symbol=EventTested], can-be-invoked-concurrently=true
        Dem_GetDTCOfEvent_GeneralEvtInfo: can-be-invoked-concurrently=true
        Dem_GetFaultDetectionCounter_GeneralEvtInfo: arguments=[symbol=EventId, symbol=FaultDetectionCounter], can-be-invoked-concurrently=true
        Dem_GetEventExtendedDataRecord_GeneralEvtInfo: can-be-invoked-concurrently=true
        Dem_GetEventFreezeFrameData_GeneralEvtInfo: can-be-invoked-concurrently=true
        Dem_GetEventExtendedDataRecordEx_GeneralEvtInfo: arguments=[symbol=EventId, symbol=RecordNumber, symbol=DestBuffer, symbol=BufSize], can-be-invoked-concurrently=true
        Dem_GetEventFreezeFrameDataEx_GeneralEvtInfo: can-be-invoked-concurrently=true
        GetDebouncingOfEvent_GeneralEvtInfo: can-be-invoked-concurrently=true, symbol=Dem_GetDebouncingOfEvent_GeneralEvtInfo
        Dem_GetEventIdCausingLastDetError: can-be-invoked-concurrently=true
        SetEventAvailable: arguments=[symbol=EventId, symbol=AvailableStatus], can-be-invoked-concurrently=true, symbol=Dem_SetEventAvailable
package /AUTOSAR_Dem/PortInterfaces
  31 x client server interface, all with is-service=true:
    DiagnosticMonitor
      6 x operation, all with possible-error=[DiagnosticMonitor/E_OK, DiagnosticMonitor/E_NOT_OK]:
        SetEventStatus
          arg EventStatus: type=Dem_EventStatusType, direction=IN
        SetEventStatusWithEnvdata
          arg EventStatus: type=Dem_EventStatusType, direction=IN
          arg debug0: type=Dem_DebugDataType, direction=IN
          arg debug1: type=Dem_DebugDataType, direction=IN
        ResetEventStatus
        PrestoreFreezeFrame
        ClearPrestoredFreezeFrame
        ResetEventDebounceStatus
          arg DebounceResetStatus: type=Dem_DebounceResetStatusType, direction=IN
      error E_OK: error-code=0
      error E_NOT_OK: error-code=1
    DiagnosticInfo
      10 x operation:
        GetEventStatus: possible-error=[DiagnosticInfo/E_OK, DiagnosticInfo/E_NOT_OK]
          arg EventStatusByte: type=Dem_UdsStatusByteType, direction=OUT
        GetEventFailed: possible-error=[DiagnosticInfo/E_OK, DiagnosticInfo/E_NOT_OK]
          arg EventFailed: type=boolean, direction=OUT
        GetEventTested: possible-error=[DiagnosticInfo/E_OK, DiagnosticInfo/E_NOT_OK]
          arg EventTested: type=boolean, direction=OUT
        GetDTCOfEvent: possible-error=[DiagnosticInfo/E_OK, DiagnosticInfo/E_NOT_OK, DiagnosticInfo/DEM_E_NO_DTC_AVAILABLE]
          arg DTCFormat: type=Dem_DTCFormatType, direction=IN
          arg DTCOfEvent: type=uint32, direction=OUT
        GetDebouncingOfEvent: possible-error=[DiagnosticInfo/E_OK, DiagnosticInfo/E_NOT_OK]
          arg DebouncingState: type=Dem_DebouncingStateType, direction=OUT
        GetFaultDetectionCounter: possible-error=[DiagnosticInfo/E_OK, DiagnosticInfo/E_NOT_OK, DiagnosticInfo/DEM_E_NO_FDC_AVAILABLE]
          arg FaultDetectionCounter: type=sint8, direction=OUT
        GetEventExtendedDataRecord: possible-error=[DiagnosticInfo/E_OK, DiagnosticInfo/E_NOT_OK]
          arg RecordNumber: type=uint8, direction=IN
          arg DestBuffer: type=Dem_MaxDataValueType, direction=OUT
        GetEventExtendedDataRecordEx: possible-error=[DiagnosticInfo/E_OK, DiagnosticInfo/E_NOT_OK]
          arg RecordNumber: type=uint8, direction=IN
          arg DestBuffer: type=Dem_MaxDataValueType, direction=OUT
          arg Bufsize: type=uint16, direction=INOUT
        GetEventFreezeFrameData: possible-error=[DiagnosticInfo/E_OK, DiagnosticInfo/E_NOT_OK]
          4 x arg:
            RecordNumber: type=uint8, direction=IN
            ReportTotalRecord: type=boolean, direction=IN
            DataId: type=uint16, direction=IN
            DestBuffer: type=Dem_MaxDataValueType, direction=OUT
        GetEventFreezeFrameDataEx: possible-error=[DiagnosticInfo/E_OK, DiagnosticInfo/E_NOT_OK]
          4 x arg:
            RecordNumber: type=uint8, direction=IN
            DataId: type=uint16, direction=IN
            DestBuffer: type=Dem_MaxDataValueType, direction=OUT
            BufSize: type=uint16, direction=INOUT
      4 x error:
        E_OK: error-code=0
        E_NOT_OK: error-code=1
        DEM_E_NO_DTC_AVAILABLE: error-code=2
        DEM_E_NO_FDC_AVAILABLE: error-code=3
    GetDataOfPID21
      operation GetDataOfPID21: possible-error=[GetDataOfPID21/E_OK, GetDataOfPID21/E_NOT_OK]
        arg PID21value: type=Dem_PID21valueType, direction=OUT
      error E_OK: error-code=0
      error E_NOT_OK: error-code=1
    GetDataOfPID31
      operation GetDataOfPID31: possible-error=[GetDataOfPID31/E_OK, GetDataOfPID31/E_NOT_OK]
        arg PID31value: type=Dem_PID31valueType, direction=OUT
      error E_OK: error-code=0
      error E_NOT_OK: error-code=1
    SetDataOfPID21
      operation SetDataOfPID21: possible-error=[SetDataOfPID21/E_OK, SetDataOfPID21/E_NOT_OK]
        arg PID21value: type=Dem_PID21valueType, direction=IN
      error E_OK: error-code=0
      error E_NOT_OK: error-code=1
    SetDataOfPID31
      operation SetDataOfPID31: possible-error=[SetDataOfPID31/E_OK, SetDataOfPID31/E_NOT_OK]
        arg PID31value: type=Dem_PID31valueType, direction=IN
      error E_OK: error-code=0
      error E_NOT_OK: error-code=1
    SetDataOfPID4D
      operation SetDataOfPID4D: possible-error=[SetDataOfPID4D/E_OK, SetDataOfPID4D/E_NOT_OK]
        arg PID4Dvalue: type=Dem_PID4DvalueType, direction=IN
      error E_OK: error-code=0
      error E_NOT_OK: error-code=1
    SetDataOfPID4E
      operation SetDataOfPID4E: possible-error=[SetDataOfPID4E/E_OK, SetDataOfPID4E/E_NOT_OK]
        arg PID4Evalue: type=Dem_PID4EvalueType, direction=IN
      error E_OK: error-code=0
      error E_NOT_OK: error-code=1
    GetDataOfPID4D
      operation GetDataOfPID4D: possible-error=[GetDataOfPID4D/E_OK, GetDataOfPID4D/E_NOT_OK]
        arg PID4Dvalue: type=Dem_PID4DvalueType, direction=OUT
      error E_OK: error-code=0
      error E_NOT_OK: error-code=1
    GetDataOfPID4E
      operation GetDataOfPID4E: possible-error=[GetDataOfPID4E/E_OK, GetDataOfPID4E/E_NOT_OK]
        arg PID4Evalue: type=Dem_PID4EvalueType, direction=OUT
      error E_OK: error-code=0
      error E_NOT_OK: error-code=1
    GeneralDiagnosticInfo
      11 x operation:
        GetEventStatus: possible-error=[GeneralDiagnosticInfo/E_OK, GeneralDiagnosticInfo/E_NOT_OK]
          arg EventId: type=Dem_EventIdType, direction=IN
          arg EventStatusByte: type=Dem_UdsStatusByteType, direction=OUT
        GetEventFailed: possible-error=[GeneralDiagnosticInfo/E_OK, GeneralDiagnosticInfo/E_NOT_OK]
          arg EventId: type=Dem_EventIdType, direction=IN
          arg EventFailed: type=boolean, direction=OUT
        GetEventTested: possible-error=[GeneralDiagnosticInfo/E_OK, GeneralDiagnosticInfo/E_NOT_OK]
          arg EventId: type=Dem_EventIdType, direction=IN
          arg EventTested: type=boolean, direction=OUT
        GetDTCOfEvent: possible-error=[GeneralDiagnosticInfo/E_OK, GeneralDiagnosticInfo/E_NOT_OK, GeneralDiagnosticInfo/DEM_E_NO_DTC_AVAILABLE]
          arg EventId: type=Dem_EventIdType, direction=IN
          arg DTCFormat: type=Dem_DTCFormatType, direction=IN
          arg DTCOfEvent: type=uint32, direction=OUT
        GetDebouncingOfEvent: possible-error=[GeneralDiagnosticInfo/E_OK, GeneralDiagnosticInfo/E_NOT_OK]
          arg EventId: type=Dem_EventIdType, direction=IN
          arg DebouncingState: type=Dem_DebouncingStateType, direction=OUT
        GetFaultDetectionCounter: possible-error=[GeneralDiagnosticInfo/E_OK, GeneralDiagnosticInfo/E_NOT_OK, GeneralDiagnosticInfo/DEM_E_NO_FDC_AVAILABLE]
          arg EventId: type=Dem_EventIdType, direction=IN
          arg FaultDetectionCounter: type=sint8, direction=OUT
        GetEventExtendedDataRecord: possible-error=[GeneralDiagnosticInfo/E_OK, GeneralDiagnosticInfo/E_NOT_OK]
          arg EventId: type=Dem_EventIdType, direction=IN
          arg RecordNumber: type=uint8, direction=IN
          arg DestBuffer: type=Dem_MaxDataValueType, direction=OUT
        GetEventFreezeFrameData: possible-error=[GeneralDiagnosticInfo/E_OK, GeneralDiagnosticInfo/E_NOT_OK]
          5 x arg:
            EventId: type=Dem_EventIdType, direction=IN
            RecordNumber: type=uint8, direction=IN
            ReportTotalRecord: type=boolean, direction=IN
            DataId: type=uint16, direction=IN
            DestBuffer: type=Dem_MaxDataValueType, direction=OUT
        GetEventExtendedDataRecordEx: possible-error=[GeneralDiagnosticInfo/E_OK, GeneralDiagnosticInfo/E_NOT_OK]
          4 x arg:
            EventId: type=Dem_EventIdType, direction=IN
            RecordNumber: type=uint8, direction=IN
            DestBuffer: type=Dem_MaxDataValueType, direction=OUT
            Bufsize: type=uint16, direction=INOUT
        GetEventFreezeFrameDataEx: possible-error=[GeneralDiagnosticInfo/E_OK, GeneralDiagnosticInfo/E_NOT_OK]
          5 x arg:
            EventId: type=Dem_EventIdType, direction=IN
            RecordNumber: type=uint8, direction=IN
            DataId: type=uint16, direction=IN
            DestBuffer: type=Dem_MaxDataValueType, direction=OUT
            BufSize: type=uint16, direction=INOUT
        GetEventIdCausingLastDetError: possible-error=[GeneralDiagnosticInfo/E_OK, GeneralDiagnosticInfo/E_NOT_OK]
          arg EventId: type=Dem_EventIdType, direction=OUT
      4 x error:
        E_OK: error-code=0
        E_NOT_OK: error-code=1
        DEM_E_NO_DTC_AVAILABLE: error-code=2
        DEM_E_NO_FDC_AVAILABLE: error-code=3
    OperationCycle
      4 x operation, all with possible-error=[OperationCycle/E_OK, OperationCycle/E_NOT_OK]:
        SetOperationCycleState
          arg CycleState: type=Dem_OperationCycleStateType, direction=IN
        GetOperationCycleState
          arg CycleState: type=Dem_OperationCycleStateType, direction=OUT
        GetCycleQualified
          arg CycleState: type=boolean, direction=OUT
        SetCycleQualified
      error E_OK: error-code=0
      error E_NOT_OK: error-code=1
    EventAvailable
      operation SetEventAvailable: possible-error=[EventAvailable/E_OK, EventAvailable/E_NOT_OK]
        arg AvailableStatus: type=boolean, direction=IN
      error E_OK: error-code=0
      error E_NOT_OK: error-code=1
    EnableCondition
      operation SetEnableCondition: possible-error=[EnableCondition/E_OK, EnableCondition/E_NOT_OK]
        arg ConditionFulfilled: type=boolean, direction=IN
      operation GetEnableCondition: possible-error=[EnableCondition/E_OK, EnableCondition/E_NOT_OK]
        arg ConditionFulfilled: type=boolean, direction=OUT
      error E_OK: error-code=0
      error E_NOT_OK: error-code=1
    StorageCondition
      operation SetStorageCondition: possible-error=[StorageCondition/E_OK, StorageCondition/E_NOT_OK]
        arg ConditionFulfilled: type=boolean, direction=IN
      operation GetStorageCondition: possible-error=[StorageCondition/E_OK, StorageCondition/E_NOT_OK]
        arg ConditionFulfilled: type=boolean, direction=OUT
      error E_OK: error-code=0
      error E_NOT_OK: error-code=1
    IndicatorStatus
      operation GetIndicatorStatus: possible-error=[IndicatorStatus/E_OK, IndicatorStatus/E_NOT_OK]
        arg IndicatorStatus: type=Dem_IndicatorStatusType, direction=OUT
      error E_OK: error-code=0
      error E_NOT_OK: error-code=1
    DTCSuppression
      operation SetDTCSuppression: possible-error=[DTCSuppression/E_OK, DTCSuppression/E_NOT_OK, DTCSuppression/DEM_WRONG_DTC, DTCSuppression/DEM_WRONG_DTCORIGIN, DTCSuppression/DEM_PENDING]
        arg SuppressionStatus: type=boolean, direction=IN
      operation GetDTCSuppression: possible-error=[DTCSuppression/E_OK, DTCSuppression/E_NOT_OK, DTCSuppression/DEM_WRONG_DTC, DTCSuppression/DEM_WRONG_DTCORIGIN, DTCSuppression/DEM_PENDING]
        arg SuppressionStatus: type=boolean, direction=OUT
      5 x error:
        E_OK: error-code=0
        E_NOT_OK: error-code=1
        DEM_PENDING: error-code=4
        DEM_WRONG_DTC: error-code=8
        DEM_WRONG_DTCORIGIN: error-code=9
    EvMemOverflowIndication
      operation GetEventMemoryOverflow: possible-error=[EvMemOverflowIndication/E_OK, EvMemOverflowIndication/E_NOT_OK]
        arg OverflowIndication: type=boolean, direction=OUT
      operation GetNumberOfEventMemoryEntries: possible-error=[EvMemOverflowIndication/E_OK, EvMemOverflowIndication/E_NOT_OK]
        arg NumberOfEventMemoryEntries: type=uint8, direction=OUT
      error E_OK: error-code=0
      error E_NOT_OK: error-code=1
    DataServices_DemDataElementClass_Year
      operation ReadData: possible-error=[DataServices_DemDataElementClass_Year/E_OK, DataServices_DemDataElementClass_Year/E_NOT_OK]
        arg Data: type=DemDataElememtDataSize_DemDataElementClass_Year, direction=OUT
      error E_OK: error-code=0
      error E_NOT_OK: error-code=1
    DataServices_DemDataElementClass_Month
      operation ReadData: possible-error=[DataServices_DemDataElementClass_Month/E_OK, DataServices_DemDataElementClass_Month/E_NOT_OK]
        arg Data: type=DemDataElememtDataSize_DemDataElementClass_Month, direction=OUT
      error E_OK: error-code=0
      error E_NOT_OK: error-code=1
    DataServices_DemDataElementClass_Day
      operation ReadData: possible-error=[DataServices_DemDataElementClass_Day/E_OK, DataServices_DemDataElementClass_Day/E_NOT_OK]
        arg Data: type=DemDataElememtDataSize_DemDataElementClass_Day, direction=OUT
      error E_OK: error-code=0
      error E_NOT_OK: error-code=1
    DataServices_DemDataElementClass_Hour
      operation ReadData: possible-error=[DataServices_DemDataElementClass_Hour/E_OK, DataServices_DemDataElementClass_Hour/E_NOT_OK]
        arg Data: type=DemDataElememtDataSize_DemDataElementClass_Hour, direction=OUT
      error E_OK: error-code=0
      error E_NOT_OK: error-code=1
    DataServices_DemDataElementClass_Minute
      operation ReadData: possible-error=[DataServices_DemDataElementClass_Minute/E_OK, DataServices_DemDataElementClass_Minute/E_NOT_OK]
        arg Data: type=DemDataElememtDataSize_DemDataElementClass_Minute, direction=OUT
      error E_OK: error-code=0
      error E_NOT_OK: error-code=1
    DataServices_CS_ExtendedDataRecord_Fault_pending_counter
      operation ReadData: possible-error=[DataServices_CS_ExtendedDataRecord_Fault_pending_counter/E_OK, DataServices_CS_ExtendedDataRecord_Fault_pending_counter/E_NOT_OK]
        arg Data: type=DemDataElememtDataSize_CS_ExtendedDataRecord_Fault_pending_counter, direction=OUT
      error E_OK: error-code=0
      error E_NOT_OK: error-code=1
    DataServices_CS_ExtendedDataRecord_Aged_counter
      operation ReadData: possible-error=[DataServices_CS_ExtendedDataRecord_Aged_counter/E_OK, DataServices_CS_ExtendedDataRecord_Aged_counter/E_NOT_OK]
        arg Data: type=DemDataElememtDataSize_CS_ExtendedDataRecord_Aged_counter, direction=OUT
      error E_OK: error-code=0
      error E_NOT_OK: error-code=1
    DataServices_DemDataElementClass_SupplyVoltage
      operation ReadData: possible-error=[DataServices_DemDataElementClass_SupplyVoltage/E_OK, DataServices_DemDataElementClass_SupplyVoltage/E_NOT_OK]
        arg Data: type=DemDataElememtDataSize_DemDataElementClass_SupplyVoltage, direction=OUT
      error E_OK: error-code=0
      error E_NOT_OK: error-code=1
    DataServices_DemDataElementClass_OdometerReading
      operation ReadData: possible-error=[DataServices_DemDataElementClass_OdometerReading/E_OK, DataServices_DemDataElementClass_OdometerReading/E_NOT_OK]
        arg Data: type=DemDataElememtDataSize_DemDataElementClass_OdometerReading, direction=OUT
      error E_OK: error-code=0
      error E_NOT_OK: error-code=1
    DataServices_DemDataElementClass_PowerMode
      operation ReadData: possible-error=[DataServices_DemDataElementClass_PowerMode/E_OK, DataServices_DemDataElementClass_PowerMode/E_NOT_OK]
        arg Data: type=DemDataElememtDataSize_DemDataElementClass_PowerMode, direction=OUT
      error E_OK: error-code=0
      error E_NOT_OK: error-code=1
    CallbackComponentStatusChanged
      operation ComponentStatusChanged
        arg ComponentFailedStatus: type=boolean, direction=IN
    EventStatus
      operation SetWIRStatus: possible-error=[EventStatus/E_OK, EventStatus/E_NOT_OK]
        arg WIRStatus: type=boolean, direction=IN
      error E_OK: error-code=0
      error E_NOT_OK: error-code=1
    ClearDTC
      operation ClearDTC: possible-error=[ClearDTC/E_OK, ClearDTC/E_NOT_OK, ClearDTC/DEM_PENDING, DEM_CLEAR_BUSY, DEM_CLEAR_MEMORY_ERROR, DEM_CLEAR_FAILED, ClearDTC/DEM_WRONG_DTC, ClearDTC/DEM_WRONG_DTCORIGIN, DEM_BUSY]
      operation SelectDTC: possible-error=[ClearDTC/E_OK, ClearDTC/E_NOT_OK]
        arg DTC: type=uint32, direction=IN
        arg DTCFormat: type=Dem_DTCFormatType, direction=IN
        arg DTCOrigin: type=Dem_DTCOriginType, direction=IN
      9 x error:
        E_OK: error-code=0
        E_NOT_OK: error-code=1
        DEM_PENDING: error-code=4
        DEM_CLEAR_BUSY: error-code=5
        DEM_CLEAR_MEMORY_ERROR: error-code=6
        DEM_CLEAR_FAILED: error-code=7
        DEM_WRONG_DTC: error-code=8
        DEM_WRONG_DTCORIGIN: error-code=9
        DEM_BUSY: error-code=22
package /AUTOSAR_Dem/SwcImplementations
  swc implementation Impl_Dem: programming-language=C, sw-version=9.0.0, swc-bsw-mapping=SwcBswMappings, vendor-id=6, behavior=IntBeh_Dem
    code-descriptors:
      code CodeDescr_Dem: artifact-descriptors=autosar-engineering-object={short-label=Code_0, category=SWSRC}
package /AUTOSAR_Dem/ImplementationDataTypes
  28 x impl type:
    Dem_EventStatusType: compu {1=DEM_EVENT_STATUS_FAILED, 4=DEM_EVENT_STATUS_FDC_THRESHOLD_REACHED, 0=DEM_EVENT_STATUS_PASSED, 3=DEM_EVENT_STATUS_PREFAILED, 2=DEM_EVENT_STATUS_PREPASSED}, implementation-data-type=uint8
    Dem_DebugDataType: implementation-data-type=uint32
    Dem_EventIdType: implementation-data-type=uint16
    Dem_UdsStatusByteType: compu {0x01=DEM_UDS_STATUS_TF, 0x02=DEM_UDS_STATUS_TFTOC, 0x04=DEM_UDS_STATUS_PDTC, 0x08=DEM_UDS_STATUS_CDTC, 0x10=DEM_UDS_STATUS_TNCSLC, 0x20=DEM_UDS_STATUS_TFSLC, 0x40=DEM_UDS_STATUS_TNCTOC, 0x80=DEM_UDS_STATUS_WIR}, implementation-data-type=uint8
    Dem_OperationCycleStateType: compu {0x01=DEM_CYCLE_STATE_END, 0x00=DEM_CYCLE_STATE_START}, implementation-data-type=uint8
    Dem_OperationCycleIdType: implementation-data-type=uint8
    Dem_MaxDataValueType: category=ARRAY, type-emitter=RTE
      element uint8: array-size=6, array-size-semantics=FIXED-SIZE, implementation-data-type=uint8
    Dem_PID21valueType: category=ARRAY, type-emitter=RTE
      element PID21value: array-size=2, array-size-semantics=FIXED-SIZE, implementation-data-type=uint8
    Dem_PID31valueType: category=ARRAY, type-emitter=RTE
      element PID31value: array-size=2, array-size-semantics=FIXED-SIZE, implementation-data-type=uint8
    Dem_PID4DvalueType: category=ARRAY, type-emitter=RTE
      element PID4Dvalue: array-size=2, array-size-semantics=FIXED-SIZE, implementation-data-type=uint8
    Dem_PID4EvalueType: category=ARRAY, type-emitter=RTE
      element PID4Evalue: array-size=2, array-size-semantics=FIXED-SIZE, implementation-data-type=uint8
    Dem_IndicatorIdType: implementation-data-type=uint8
    Dem_IndicatorStatusType: compu {0x00=DEM_INDICATOR_OFF, 0x01=DEM_INDICATOR_CONTINUOUS, 0x02=DEM_INDICATOR_BLINKING, 0x03=DEM_INDICATOR_BLINK_CONT, 0x04=DEM_INDICATOR_SLOW_FLASH, 0x05=DEM_INDICATOR_FAST_FLASH}, implementation-data-type=uint8
    Dem_DTCOriginType: compu {0x0001=DEM_DTC_ORIGIN_PRIMARY_MEMORY, 0x0002=DEM_DTC_ORIGIN_MIRROR_MEMORY, 0x0003=DEM_DTC_ORIGIN_PERMANENT_MEMORY, 0x0004=DEM_DTC_ORIGIN_OBD_RELEVANT_MEMORY, 0x0005=DEM_DTC_ORIGIN_SECONDARY_MEMORY}, implementation-data-type=uint16
    Dem_InitMonitorReasonType: compu {0x01=DEM_INIT_MONITOR_CLEAR, 0x02=DEM_INIT_MONITOR_RESTART, 0x03=DEM_INIT_MONITOR_REENABLED, 0x04=DEM_INIT_MONITOR_STORAGE_REENABLED}, implementation-data-type=uint8
    Dem_DTCFormatType: compu {0=DEM_DTC_FORMAT_OBD, 1=DEM_DTC_FORMAT_UDS, 2=DEM_DTC_FORMAT_J1939}, implementation-data-type=uint8
    Dem_DebouncingStateType: compu {0x01=DEM_TEMPORARILY_DEFECTIVE, 0x02=DEM_FINALLY_DEFECTIVE, 0x04=DEM_TEMPORARILY_HEALED, 0x08=DEM_TEST_COMPLETE, 0x10=DEM_DTR_UPDATE}, implementation-data-type=uint8
    Dem_DebounceResetStatusType: compu {0x00=DEM_DEBOUNCE_STATUS_FREEZE, 0x01=DEM_DEBOUNCE_STATUS_RESET}, implementation-data-type=uint8
    DemDataElememtDataSize_DemDataElementClass_Year: category=ARRAY
      element DemDataElememtDataSize_DemDataElementClass_Year: array-size=2, array-size-semantics=FIXED-SIZE, implementation-data-type=uint8
    DemDataElememtDataSize_DemDataElementClass_Month: category=ARRAY
      element DemDataElememtDataSize_DemDataElementClass_Month: array-size=1, array-size-semantics=FIXED-SIZE, implementation-data-type=uint8
    DemDataElememtDataSize_DemDataElementClass_Day: category=ARRAY
      element DemDataElememtDataSize_DemDataElementClass_Day: array-size=1, array-size-semantics=FIXED-SIZE, implementation-data-type=uint8
    DemDataElememtDataSize_DemDataElementClass_Hour: category=ARRAY
      element DemDataElememtDataSize_DemDataElementClass_Hour: array-size=1, array-size-semantics=FIXED-SIZE, implementation-data-type=uint8
    DemDataElememtDataSize_DemDataElementClass_Minute: category=ARRAY
      element DemDataElememtDataSize_DemDataElementClass_Minute: array-size=1, array-size-semantics=FIXED-SIZE, implementation-data-type=uint8
    DemDataElememtDataSize_CS_ExtendedDataRecord_Fault_pending_counter: category=ARRAY
      element DemDataElememtDataSize_CS_ExtendedDataRecord_Fault_pending_counter: array-size=1, array-size-semantics=FIXED-SIZE, implementation-data-type=uint8
    DemDataElememtDataSize_CS_ExtendedDataRecord_Aged_counter: category=ARRAY
      element DemDataElememtDataSize_CS_ExtendedDataRecord_Aged_counter: array-size=1, array-size-semantics=FIXED-SIZE, implementation-data-type=uint8
    DemDataElememtDataSize_DemDataElementClass_SupplyVoltage: category=ARRAY
      element DemDataElememtDataSize_DemDataElementClass_SupplyVoltage: array-size=1, array-size-semantics=FIXED-SIZE, implementation-data-type=uint8
    DemDataElememtDataSize_DemDataElementClass_OdometerReading: category=ARRAY
      element DemDataElememtDataSize_DemDataElementClass_OdometerReading: array-size=3, array-size-semantics=FIXED-SIZE, implementation-data-type=uint8
    DemDataElememtDataSize_DemDataElementClass_PowerMode: category=ARRAY
      element DemDataElememtDataSize_DemDataElementClass_PowerMode: array-size=1, array-size-semantics=FIXED-SIZE, implementation-data-type=uint8
package /AUTOSAR_Dem/SwcBswMappings
  swc bsw mapping SwcBswMappings: bsw-behavior=IB_Dem, swc-bsw-runnable-mapping{bsw-entity=BSWSE_DemMainFunction, swc-runnable=Dem_MainFunction}, swc-behavior=IntBeh_Dem
